# MSPM0C110X register map
Vendor: Texas Instruments; File version: This preliminary header file does not have a version number - build date: 2024-04-30 10:45:50
CPU: CM0 r0p1, little endian, MPU, no FPU, 3 interrupt priority bits
Registers are 32-bit, read-write, reset 0x0 unless marked. A register's access mark holds for its fields unless they carry their own. Offsets are from the block's base; [hi:lo] are bit positions; lines under a group give offsets from that group; {n}, {i} and the like mark numbered series; 'fields as' and 'values as' point back to an identical list.

## CRC — PERIPHERALREGION
Base 0x40440000
{0x800+0x18*i} CRC_GPRCM[{i}] (i=0..0) group
  0x00 CRC_PWREN — Power enable
    [0] ENABLE — Enable the power
      0=DISABLE (Disable Power); 1=ENABLE (Enable Power)
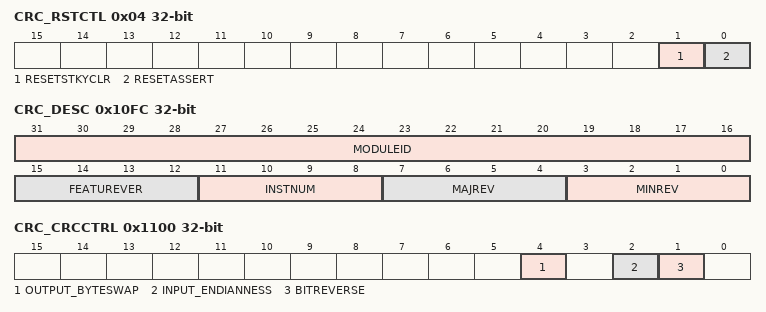
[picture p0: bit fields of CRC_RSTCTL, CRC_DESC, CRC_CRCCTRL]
  0x04 CRC_RSTCTL wo — Reset Control
    [1] RESETSTKYCLR — Clear the RESETSTKY bit in the STAT register
      0=NOP (Writing 0 has no effect); 1=CLR (Clear reset sticky bit)
    [0] RESETASSERT — Assert reset to the peripheral
      0=NOP (Writing 0 has no effect); 1=ASSERT (Assert reset)
  0x14 CRC_STAT ro — Status Register
    [16] RESETSTKY — This bit indicates, if the peripheral was reset, since this bit was cleared by RESETSTKYCLR in the RSTCTL register
      0=NORES (The peripheral has not been reset since this bit was last cleared by RESETSTKYCLR in the RSTCTL register); 1=RESET (The peripheral was reset since the last bit clear)
0x10FC CRC_DESC ro — Module Description
  [31:16] MODULEID — Module identification contains a unique peripheral identification number. The assignments are maintained in a central database for all of the platform modules to ensure uniqueness.
  [15:12] FEATUREVER — Feature Set for the module *instance*
  [11:8] INSTNUM — Instance Number within the device. This will be a parameter to the RTL for modules that can have multiple instances
  [7:4] MAJREV — Major rev of the IP
  [3:0] MINREV — Minor rev of the IP
0x1100 CRC_CRCCTRL — CRC Control Register
  [4] OUTPUT_BYTESWAP — CRC Output Byteswap Enable. This bit controls whether the output is byte-swapped upon a read of the CRCOUT register. If CRCOUT is accessed as a half-word, and the OUTPUT_BYTESWAP is set to to 1, then the two bytes in the 16-bit access are swapped and returned. B1 is returned as B0 B0 is returned as B1 If CRCOUT is accessed as a word, and the OUTPUT_BYTESWAP is set to 1, then the four bytes in the 32-bit read are swapped. B3 is returned as B0 B2 is returned as B1 B1 is returned as B2 B0 is returned as B3 Note that if the CRC POLYSIZE is 16-bit and a 32-bit read of CRCOUT is performed with OUTPUT_BYTESWAP enabled, then the output is: MSB LSB 0x0 0x0 B0 B1 If the CRC POLYSIZE is 16-bit and a 32-bit read of CRCOUT is performed with OUTPUT_BYTESWAP disabled, then the output is: MSB LSB 0x0 0x0 B1 B0
    0=DISABLE (Output byteswapping is disabled); 1=ENABLE (Output byteswapping is enabled.)
  [2] INPUT_ENDIANNESS — CRC Endian. This bit indicates the byte order within a word or half word of input data.
    0=LITTLE_ENDIAN (LSB is lowest memory address and first to be processed.); 1=BIG_ENDIAN (LSB is highest memory address and last to be processed.)
  [1] BITREVERSE — CRC Bit Input and output Reverse. This bit indicates that the bit order of each input byte used for the CRC calculation is reversed before it is passed to the generator, and that the bit order of the calculated CRC is be reversed when read from CRC_RESULT.
    0=NOT_REVERSED (Bit order is not reversed.); 1=REVERSED (Bit order is reversed.)
0x1104 CRC_CRCSEED wo — CRC Seed Register
  [31:0] SEED — Seed Data
0x1108 CRC_CRCIN wo — CRC Input Data Register
  [31:0] DATA — Input Data
0x110C CRC_CRCOUT ro — CRC Output Result Register
  [31:0] RESULT
{0x1800+4i} CRC_CRCIN_IDX[{i}] (i=0..511) wo — CRC Input Data Array Register
  [31:0] DATA — Input Data

## CPUSS — CPUSSMMR
Base 0x40400000
0x10E0 CPUSS_EVT_MODE ro — Event Mode
  [1:0] INT_CFG — Event line mode select
    0=DISABLE (The interrupt or event line is disabled.); 1=SOFTWARE (Event handled by software. Software must clear the associated RIS flag.); 2=HARDWARE (Event handled by hardware. The hardware (another module) clears automatically the associated RIS flag.)
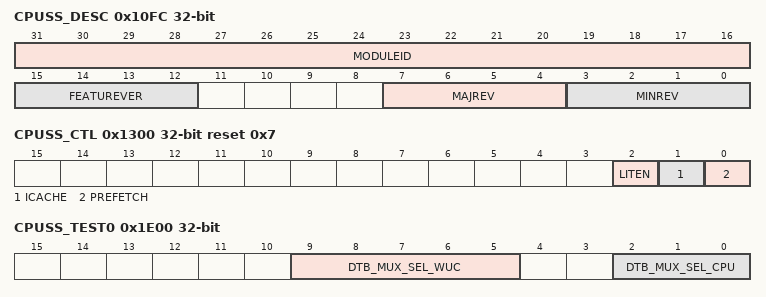
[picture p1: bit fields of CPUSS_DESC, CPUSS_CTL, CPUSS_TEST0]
0x10FC CPUSS_DESC ro — Module Description
  [31:16] MODULEID — Module identification contains a unique peripheral identification number. The assignments are maintained in a central database for all of the platform modules to ensure uniqueness.
  [15:12] FEATUREVER — Feature Set for the module *instance*
  [7:4] MAJREV — Major rev of the IP
  [3:0] MINREV — Minor rev of the IP
0x1100 CPUSS_IIDX ro — Interrupt index
  [7:0] STAT — Interrupt index status
    0=NO_INTR (No pending interrupt); {v}=INT{v-1} (Interrupt {v-1}) (v=1..8)
0x1108 CPUSS_IMASK ro reset 0xFF — Interrupt mask
  [7:0] INT — Masks the corresponding interrupt
    1=Interrupt 0; 2=Interrupt 1; 4=Interrupt 2; 8=Interrupt 3; 16=Interrupt 4; 32=Interrupt 5; 64=Interrupt 6; 128=Interrupt 7
0x1110 CPUSS_RIS ro — Raw interrupt status
  [7:0] INT — Raw interrupt status for INT
    values as CPUSS_IMASK.INT
0x1118 CPUSS_MIS ro — Masked interrupt status
  [7:0] INT — Masked interrupt status for INT0
    values as CPUSS_IMASK.INT
0x1120 CPUSS_ISET wo — Interrupt set
  [7:0] INT — Sets INT in RIS register
    values as CPUSS_IMASK.INT
0x1128 CPUSS_ICLR wo — Interrupt clear
  [7:0] INT — Clears INT in RIS register
    values as CPUSS_IMASK.INT
0x1300 CPUSS_CTL reset 0x7 — Prefetch/Cache control
  [2] LITEN — Literal caching and prefetch enable. This bit is a subset of ICACHE/PREFETCH bit i.e. literal caching or literal prefetching will only happen if ICACHE or PREFETCH bits have been set respectively When enabled, the cache and prefetcher structures inside CPUSS will cache and prefetch literals When disabled, the cache and prefetcher structures inside CPUSS will not cache and prefetch literals
    0=DISABLE (Literal caching disabled); 1=ENABLE (Literal caching enabled)
  [1] ICACHE — Used to enable/disable Instruction caching on flash access.
    0=DISABLE (Disable instruction caching.); 1=ENABLE (Enable instruction caching.)
  [0] PREFETCH — Used to enable/disable instruction prefetch to Flash.
    0=DISABLE (Disable instruction prefetch.); 1=ENABLE (Enable instruction prefetch.)
0x1E00 CPUSS_TEST0 — DTB MUX Sel
  [9:5] DTB_MUX_SEL_WUC — DTB Mux Sel Refer to implementaion spec for mux selection table.
  [2:0] DTB_MUX_SEL_CPU — DTB Mux Sel Refer to implementaion spec for mux selection table.

## ADC0_SVT — PERIPHERALREGIONSVT
Base 0x4055A000
0x556160 ADC0_SVT_FIFODATA ro — FIFO Data Register
{0x556280+4i} ADC0_SVT_MEMRES[{i}] (i=0..3) ro — Memory Result Register
  [15:0] DATA — MEMRES result register. If DF = 0, unsigned binary: The conversion results are right aligned. In 10 and 8 bit modes, the unused MSB bits are forced to 0. If DF = 1, 2s-complement format: The conversion results are left aligned. In 10 and 8 bit modes, the unused LSB bits are forced to 0. The data is stored in the right-justified format and is converted to the left-justified 2s-complement format during read back.

## WUC — PERIPHERALREGION
Base 0x40424000
0x400 WUC_FSUB_0 — Subscriber Port 0
  [1:0] CHANID — 0 = disconnected. 1-15 = connected to channelID = CHANID.
    0=UNCONNECTED (A value of 0 specifies that the event is not connected)
0x404 WUC_FSUB_1 — Subscriber Port 1
  fields as WUC_FSUB_0

## VREF — PERIPHERALREGION
Base 0x40030000
{0x800+0x18*i} VREF_GPRCM[{i}] (i=0..0) group
  0x00 VREF_PWREN — Power enable
    [0] ENABLE — Enable the power
      0=DISABLE (Disable Power); 1=ENABLE (Enable Power)
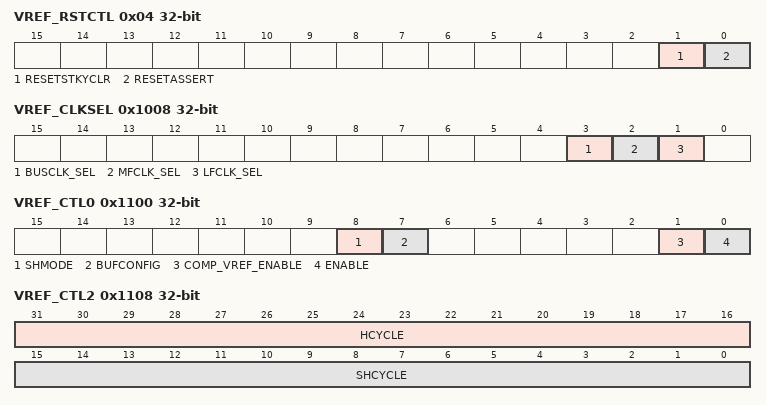
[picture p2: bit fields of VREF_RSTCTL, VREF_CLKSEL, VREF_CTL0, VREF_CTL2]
  0x04 VREF_RSTCTL wo — Reset Control
    [1] RESETSTKYCLR — Clear the RESETSTKY bit in the STAT register
      0=NOP (Writing 0 has no effect); 1=CLR (Clear reset sticky bit)
    [0] RESETASSERT — Assert reset to the peripheral
      0=NOP (Writing 0 has no effect); 1=ASSERT (Assert reset)
  0x14 VREF_STAT ro — Status Register
    [16] RESETSTKY — This bit indicates, if the peripheral was reset, since this bit was cleared by RESETSTKYCLR in the RSTCTL register
      0=NORES (The peripheral has not been reset since this bit was last cleared by RESETSTKYCLR in the RSTCTL register); 1=RESET (The peripheral was reset since the last bit clear)
0x1000 VREF_CLKDIV — Clock Divider
  [2:0] RATIO — Selects divide ratio of module clock to be used in sample and hold logic
0x1008 VREF_CLKSEL — Clock Selection
  [3] BUSCLK_SEL — Selects BUSCLK as clock source if enabled
  [2] MFCLK_SEL — Selects MFCLK as clock source if enabled
  [1] LFCLK_SEL — Selects LFCLK as clock source if enabled
0x1100 VREF_CTL0 — Control 0
  [8] SHMODE — This bit enable sample and hold mode
    0=DISABLE (Sample and hold mode is disable); 1=Enable (Sample and hold mode is enable)
  [7] BUFCONFIG — These bits configure output buffer.
    0=OUTPUT2P5V (Configure Output Buffer to 2.5v); 1=OUTPUT1P4V (Configure Output Buffer to 1.4v)
  [1] COMP_VREF_ENABLE — Comparator Vref Enable
    0=DISABLE (COMP VREF is disabled); 1=ENABLE (COMP VREF is enabled)
  [0] ENABLE — This bit enables the VREF module.
    0=DISABLE (VREF is disabled); 1=ENABLE (VREF is enabled)
0x1104 VREF_CTL1 — Control 1
  [0] READY ro — These bits defines status of VREF
    0=NOTRDY (VREF output is not ready); 1=RDY (VREF output is ready)
0x1108 VREF_CTL2 — Control 2
  [31:16] HCYCLE — Hold cycle count Total cycles of module clock for hold phase when VREF is working in sample and hold mode in STANDBY to save power. Please refer VREF section of datasheet for recommended values of sample and hold times.
  [15:0] SHCYCLE — Sample and Hold cycle count Total cycles of module clock for sample and hold phase when VREF is working in sample and hold mode in STANDBY to save power. This field should be greater than HCYCLE field. The difference between this field and HCYCLE gives the number of cycles of sample phase. Please refer VREF section of datasheet for recommended values of sample and hold times.
